VERSION ""

NS_ :

BS_:

BU_:
VAL_TABLE_ Board_ID_2 7 "Board 6" 5 "Board 4" 3 "Board 8" 1 "Board 2" ;
VAL_TABLE_ Board_ID_1 6 "Board 7" 4 "Board 5" 2 "Board 3" 0 "Board 1" ;

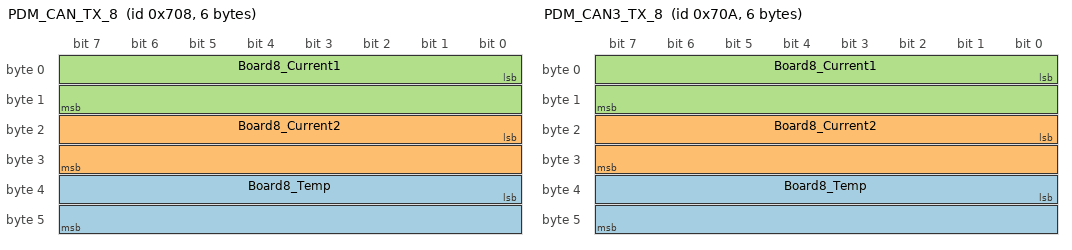
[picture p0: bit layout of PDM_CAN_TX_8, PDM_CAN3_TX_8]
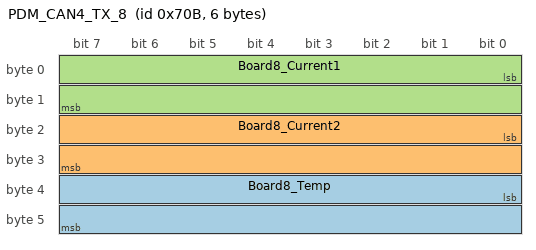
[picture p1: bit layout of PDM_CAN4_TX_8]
BO_ 1800 PDM_CAN_TX_8: 6 Vector__XXX
 SG_ Board8_Temp : 32|16@1- (1,0) [0|0] "" Vector__XXX
 SG_ Board8_Current2 : 16|16@1- (1,0) [0|0] "" Vector__XXX
 SG_ Board8_Current1 : 0|16@1- (1,0) [0|0] "" Vector__XXX

BO_ 1801 PDM_CAN2_TX_8: 6 Vector__XXX
 SG_ Board8_Temp :  33|16@1- (1,0) [0|0] "" Vector__XXX
 SG_ Board8_Current2 : 17|16@1- (1,0) [0|0] "" Vector__XXX
 SG_ Board8_Current1 : 1|16@1- (1,0) [0|0] "" Vector__XXX

BO_ 1802 PDM_CAN3_TX_8: 6 Vector__XXX
 SG_ Board8_Temp :  32|16@1+ (1,0) [0|0] "" Vector__XXX
 SG_ Board8_Current2 : 16|16@1+ (1,0) [0|0] "" Vector__XXX
 SG_ Board8_Current1 : 0|16@1+ (1,0) [0|0] "" Vector__XXX

 BO_ 1803 PDM_CAN4_TX_8: 6 Vector__XXX
 SG_ Board8_Temp : 32|16@1- (0.1,0) [0|0] "" Vector__XXX
 SG_ Board8_Current2 : 16|16@1- (4,0) [0|0] "" Vector__XXX
 SG_ Board8_Current1 : 0|16@1- (1,10) [0|0] "" Vector__XXX

BA_DEF_  "BusType" STRING ;
BA_DEF_DEF_  "BusType" "CAN";
